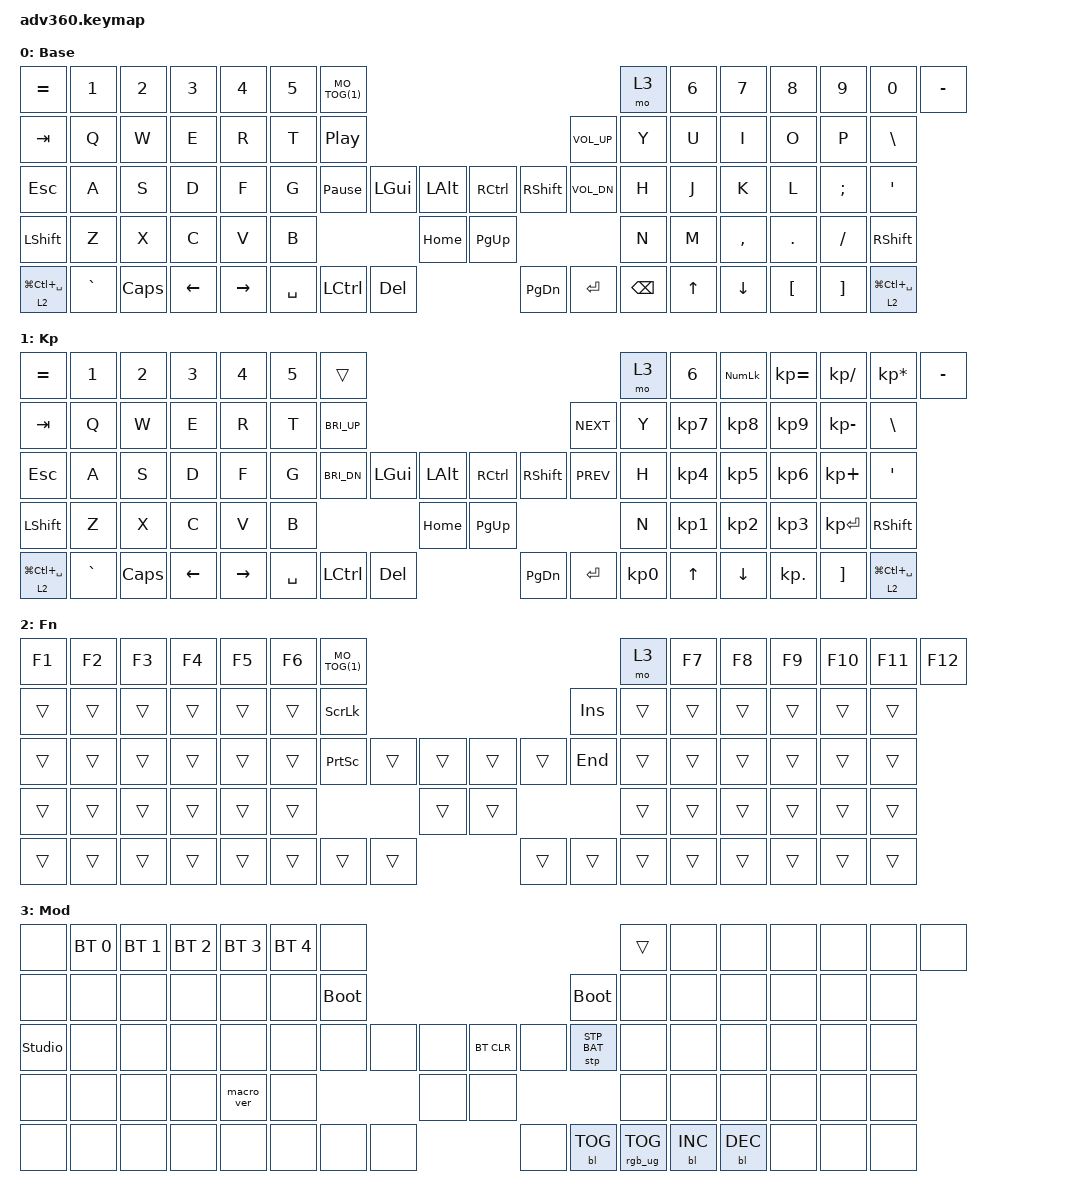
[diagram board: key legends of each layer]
/*
 * Copyright (c) 2020 The ZMK Contributors
 * Modified by Jonathan Ming
 *
 * SPDX-License-Identifier: MIT
 */

#include <behaviors.dtsi>
#include <dt-bindings/zmk/keys.h>
#include <dt-bindings/zmk/bt.h>
#include <dt-bindings/zmk/rgb.h>
#include <dt-bindings/zmk/stp.h>
#include <dt-bindings/zmk/backlight.h>
#include <dt-bindings/zmk/pointing.h>

// From https://zmk.dev/docs/behaviors/hold-tap#example-use-cases
#define MO_TOG(layer) &mo_tog layer layer   // Macro to apply momentary-layer-on-hold/toggle-layer-on-tap to a specific layer

/ {
  behaviors {
    #include "macros.dtsi"
    #include "version.dtsi"

    mo_tog: behavior_mo_tog {
      compatible = "zmk,behavior-hold-tap";
      label = "mo_tog";
      #binding-cells = <2>;
      flavor = "hold-preferred";
      tapping-term-ms = <200>;
      bindings = <&mo>, <&tog>;
    };
  };

  keymap {
    compatible = "zmk,keymap";

    default_layer {
      display-name = "Base";
      bindings = <
        &kp EQUAL           &kp N1    &kp N2   &kp N3   &kp N4     &kp N5 MO_TOG(1)                                                                         &mo 3 &kp N6 &kp N7 &kp N8    &kp N9   &kp N0   &kp MINUS
        &kp TAB             &kp Q     &kp W    &kp E    &kp R      &kp T  &kp C_PLAY_PAUSE                                                           &kp C_VOL_UP &kp Y  &kp U  &kp I     &kp O    &kp P    &kp BSLH
        &kp ESC             &kp A     &kp S    &kp D    &kp F      &kp G  &kp PAUSE_BREAK            &kp LGUI  &kp LALT &kp RCTRL &kp RSHFT          &kp C_VOL_DN &kp H  &kp J  &kp K     &kp L    &kp SEMI &kp SQT
        &kp LSHFT           &kp Z     &kp X    &kp C    &kp V      &kp B                                       &kp HOME &kp PG_UP                                 &kp N  &kp M  &kp COMMA &kp DOT  &kp FSLH &kp RSHFT
        &lt 2 LG(LC(SPACE)) &kp GRAVE &kp CAPS &kp LEFT &kp RIGHT                         &kp SPACE  &kp LCTRL &kp DEL  &kp PG_DN &kp ENTER &kp BSPC                     &kp UP &kp DOWN  &kp LBKT &kp RBKT &lt 2 LG(LC(SPACE))
      >;
    };
    keypad {
      display-name = "Kp";
      bindings = <
        &kp EQUAL           &kp N1    &kp N2   &kp N3   &kp N4     &kp N5 &trans                                                                       &mo 3 &kp N6 &kp KP_NUM &kp KP_EQUAL &kp KP_DIVIDE &kp KP_MULTIPLY &kp MINUS
        &kp TAB             &kp Q     &kp W    &kp E    &kp R      &kp T  &kp C_BRI_UP                                                            &kp C_NEXT &kp Y  &kp KP_N7  &kp KP_N8    &kp KP_N9     &kp KP_MINUS    &kp BSLH
        &kp ESC             &kp A     &kp S    &kp D    &kp F      &kp G  &kp C_BRI_DN           &kp LGUI  &kp LALT &kp RCTRL &kp RSHFT           &kp C_PREV &kp H  &kp KP_N4  &kp KP_N5    &kp KP_N6     &kp KP_PLUS     &kp SQT
        &kp LSHFT           &kp Z     &kp X    &kp C    &kp V      &kp B                                   &kp HOME &kp PG_UP                                &kp N  &kp KP_N1  &kp KP_N2    &kp KP_N3     &kp KP_ENTER    &kp RSHFT
        &lt 2 LG(LC(SPACE)) &kp GRAVE &kp CAPS &kp LEFT &kp RIGHT                      &kp SPACE &kp LCTRL &kp DEL  &kp PG_DN &kp ENTER &kp KP_N0                   &kp UP     &kp DOWN     &kp KP_DOT    &kp RBKT        &lt 2 LG(LC(SPACE))
      >;
    };
    fn {
      display-name = "Fn";
      bindings = <
        &kp F1 &kp F2 &kp F3 &kp F4 &kp F5 &kp F6 MO_TOG(1)                                             &mo 3 &kp F7 &kp F8 &kp F9 &kp F10 &kp F11 &kp F12
        &trans &trans &trans &trans &trans &trans &kp SLCK                                            &kp INS &trans &trans &trans &trans  &trans  &trans
        &trans &trans &trans &trans &trans &trans &kp PSCRN        &trans &trans &trans &trans        &kp END &trans &trans &trans &trans  &trans  &trans
        &trans &trans &trans &trans &trans &trans                         &trans &trans                       &trans &trans &trans &trans  &trans  &trans
        &trans &trans &trans &trans &trans                  &trans &trans &trans &trans &trans &trans                &trans &trans &trans  &trans  &trans
      >;
    };
    mod {
      display-name = "Mod";
      bindings = <
        &none          &bt BT_SEL 0 &bt BT_SEL 1 &bt BT_SEL 2 &bt BT_SEL 3 &bt BT_SEL 4 &none                                                               &trans       &none &none      &none      &none &none &none
        &none          &none        &none        &none        &none        &none        &bootloader                                                         &bootloader  &none &none      &none      &none &none &none
        &studio_unlock &none        &none        &none        &none        &none        &none             &none &none &bt BT_CLR &none                      &stp STP_BAT &none &none      &none      &none &none &none
        &none          &none        &none        &none        &macro_ver   &none                                &none &none                                              &none &none      &none      &none &none &none
        &none          &none        &none        &none        &none                                 &none &none &none &none      &bl BL_TOG &rgb_ug RGB_TOG                    &bl BL_INC &bl BL_DEC &none &none &none
      >;
    };
    extra1 { 
      display-name = "Red";    
      status = "reserved";
    };

    extra2 { 
      display-name = "Purple";    
      status = "reserved";
    };

    extra3 { 
      display-name = "Cyan";    
      status = "reserved";
    };

    extra4 { 
      display-name = "Yellow";    
      status = "reserved";
    };
  };
};
